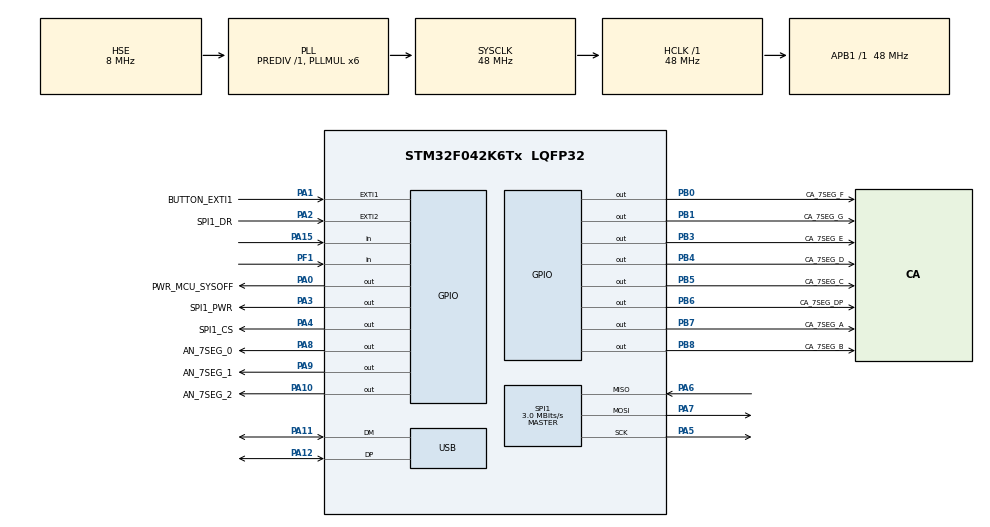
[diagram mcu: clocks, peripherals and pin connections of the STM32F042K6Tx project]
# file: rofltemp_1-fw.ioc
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Mcu.Family=STM32F0
Mcu.Name=STM32F042K6Tx
Mcu.Package=LQFP32
NVIC.EXTI0_1_IRQn=true\:0\:0\:false\:false\:true\:true
NVIC.EXTI2_3_IRQn=true\:0\:0\:false\:false\:true\:true
NVIC.SPI1_IRQn=true\:0\:0\:false\:false\:true\:true
NVIC.TIM2_IRQn=true\:0\:0\:false\:false\:true\:true
NVIC.USB_IRQn=true\:0\:0\:false\:false\:true\:true
PA0.GPIO_Label=PWR_MCU_SYSOFF
PA0.GPIO_ModeDefaultOutputPP=GPIO_MODE_OUTPUT_PP
PA0.PinState=GPIO_PIN_SET
PA0.Signal=GPIO_Output
PA1.GPIO_Label=BUTTON_EXTI1
PA1.GPIO_ModeDefaultEXTI=GPIO_MODE_IT_FALLING
PA1.Signal=GPXTI1
PA10.GPIO_Label=AN_7SEG_2
PA10.GPIO_Speed=GPIO_SPEED_FREQ_MEDIUM
PA10.PinState=GPIO_PIN_SET
PA10.Signal=GPIO_Output
PA11.Mode=Device
PA11.Signal=USB_DM
PA12.Mode=Device
PA12.Signal=USB_DP
PA13.Mode=Serial_Wire
PA13.Signal=SYS_SWDIO
PA14.Mode=Serial_Wire
PA14.Signal=SYS_SWCLK
PA15.Signal=GPIO_Input
PA2.GPIO_Label=SPI1_DR
PA2.GPIO_ModeDefaultEXTI=GPIO_MODE_IT_FALLING
PA2.GPIO_PuPd=GPIO_PULLUP
PA2.Signal=GPXTI2
PA3.GPIO_Label=SPI1_PWR
PA3.GPIO_PuPd=GPIO_NOPULL
PA3.Signal=GPIO_Output
PA4.GPIO_Label=SPI1_CS
PA4.Signal=GPIO_Output
PA5.Mode=Full_Duplex_Master
PA5.Signal=SPI1_SCK
PA6.Mode=Full_Duplex_Master
PA6.Signal=SPI1_MISO
PA7.Mode=Full_Duplex_Master
PA7.Signal=SPI1_MOSI
PA8.GPIO_Label=AN_7SEG_0
PA8.GPIO_Speed=GPIO_SPEED_FREQ_MEDIUM
PA8.PinState=GPIO_PIN_SET
PA8.Signal=GPIO_Output
PA9.GPIO_FMA9=__NULL
PA9.GPIO_Label=AN_7SEG_1
PA9.GPIO_Speed=GPIO_SPEED_FREQ_MEDIUM
PA9.PinState=GPIO_PIN_SET
PA9.Signal=GPIO_Output
PB0.GPIO_Label=CA_7SEG_F
PB0.GPIO_Speed=GPIO_SPEED_FREQ_MEDIUM
PB0.Signal=GPIO_Output
PB1.GPIO_Label=CA_7SEG_G
PB1.GPIO_Speed=GPIO_SPEED_FREQ_MEDIUM
PB1.Signal=GPIO_Output
PB3.GPIO_Label=CA_7SEG_E
PB3.GPIO_Speed=GPIO_SPEED_FREQ_MEDIUM
PB3.Signal=GPIO_Output
PB4.GPIO_Label=CA_7SEG_D
PB4.GPIO_Speed=GPIO_SPEED_FREQ_MEDIUM
PB4.Signal=GPIO_Output
PB5.GPIO_Label=CA_7SEG_C
PB5.GPIO_Speed=GPIO_SPEED_FREQ_MEDIUM
PB5.Signal=GPIO_Output
PB6.GPIO_Label=CA_7SEG_DP
PB6.GPIO_Speed=GPIO_SPEED_FREQ_MEDIUM
PB6.Signal=GPIO_Output
PB7.GPIO_Label=CA_7SEG_A
PB7.GPIO_Speed=GPIO_SPEED_FREQ_MEDIUM
PB7.Signal=GPIO_Output
PB8.GPIO_Label=CA_7SEG_B
PB8.GPIO_Speed=GPIO_SPEED_FREQ_MEDIUM
PB8.Signal=GPIO_Output
PF0-OSC_IN.Mode=HSE-External-Clock-Source
PF0-OSC_IN.Signal=RCC_OSC_IN
PF1-OSC_OUT.Signal=GPIO_Input
ProjectManager.HeapSize=0x200
ProjectManager.StackSize=0x400
ProjectManager.TargetToolchain=SW4STM32
RCC.AHBFreq_Value=48000000
RCC.APB1Freq_Value=48000000
RCC.APB1TimFreq_Value=48000000
RCC.HCLKFreq_Value=48000000
RCC.PLLMUL=RCC_PLL_MUL6
RCC.SYSCLKFreq_VALUE=48000000
RCC.SYSCLKSource=RCC_SYSCLKSOURCE_PLLCLK
RCC.USBClockSelection=RCC_USBCLKSOURCE_PLL
RCC.USBFreq_Value=48000000
RCC.VDD_VALUE=3.3
SPI1.BaudRatePrescaler=SPI_BAUDRATEPRESCALER_16
SPI1.CLKPhase=SPI_PHASE_2EDGE
SPI1.CLKPolarity=SPI_POLARITY_HIGH
SPI1.CalculateBaudRate=3.0 MBits/s
SPI1.DataSize=SPI_DATASIZE_8BIT
SPI1.Direction=SPI_DIRECTION_2LINES
SPI1.Mode=SPI_MODE_MASTER
SPI1.VirtualType=VM_MASTER
TIM2.Channel-PWM\ Generation1\ No\ Output=TIM_CHANNEL_1
TIM2.Period=1000
TIM2.Prescaler=120
TIM2.Pulse-PWM\ Generation1\ No\ Output=500
TIM2.TIM_MasterOutputTrigger=TIM_TRGO_RESET
TIM2.TIM_MasterSlaveMode=TIM_MASTERSLAVEMODE_DISABLE
USB.lpm_enable=ENABLE
USB_DEVICE.CLASS_NAME_FS=CDC
USB_DEVICE.VirtualMode=Cdc
USB_DEVICE.VirtualModeFS=Cdc_FS
VP_TIM2_VS_ClockSourceINT.Mode=Internal
VP_TIM2_VS_no_output1.Mode=PWM Generation1 No Output
VP_USB_DEVICE_VS_USB_DEVICE_CDC_FS.Mode=CDC_FS
board=rofltemp_1-fw

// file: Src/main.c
/**
  ******************************************************************************
  * File Name          : main.c
  * Description        : Main program body
  ******************************************************************************
  * This notice applies to any and all portions of this file
  * that are not between comment pairs USER CODE BEGIN and
  * USER CODE END. Other portions of this file, whether
  * inserted by the user or by software development tools
  * are owned by their respective copyright owners.
  *
  * Copyright (c) 2017 STMicroelectronics International N.V.
  * All rights reserved.
  *
  * Redistribution and use in source and binary forms, with or without
  * modification, are permitted, provided that the following conditions are met:
  *
  * 1. Redistribution of source code must retain the above copyright notice,
  *    this list of conditions and the following disclaimer.
  * 2. Redistributions in binary form must reproduce the above copyright notice,
  *    this list of conditions and the following disclaimer in the documentation
  *    and/or other materials provided with the distribution.
  * 3. Neither the name of STMicroelectronics nor the names of other
  *    contributors to this software may be used to endorse or promote products
  *    derived from this software without specific written permission.
  * 4. This software, including modifications and/or derivative works of this
  *    software, must execute solely and exclusively on microcontroller or
  *    microprocessor devices manufactured by or for STMicroelectronics.
  * 5. Redistribution and use of this software other than as permitted under
  *    this license is void and will automatically terminate your rights under
  *    this license.
  *
  * THIS SOFTWARE IS PROVIDED BY STMICROELECTRONICS AND CONTRIBUTORS "AS IS"
  * AND ANY EXPRESS, IMPLIED OR STATUTORY WARRANTIES, INCLUDING, BUT NOT
  * LIMITED TO, THE IMPLIED WARRANTIES OF MERCHANTABILITY, FITNESS FOR A
  * PARTICULAR PURPOSE AND NON-INFRINGEMENT OF THIRD PARTY INTELLECTUAL PROPERTY
  * RIGHTS ARE DISCLAIMED TO THE FULLEST EXTENT PERMITTED BY LAW. IN NO EVENT
  * SHALL STMICROELECTRONICS OR CONTRIBUTORS BE LIABLE FOR ANY DIRECT, INDIRECT,
  * INCIDENTAL, SPECIAL, EXEMPLARY, OR CONSEQUENTIAL DAMAGES (INCLUDING, BUT NOT
  * LIMITED TO, PROCUREMENT OF SUBSTITUTE GOODS OR SERVICES; LOSS OF USE, DATA,
  * OR PROFITS; OR BUSINESS INTERRUPTION) HOWEVER CAUSED AND ON ANY THEORY OF
  * LIABILITY, WHETHER IN CONTRACT, STRICT LIABILITY, OR TORT (INCLUDING
  * NEGLIGENCE OR OTHERWISE) ARISING IN ANY WAY OUT OF THE USE OF THIS SOFTWARE,
  * EVEN IF ADVISED OF THE POSSIBILITY OF SUCH DAMAGE.
  *
  ******************************************************************************
  */
#include "main.h"
#include "stm32f0xx_hal.h"
#include "spi.h"
#include "tim.h"
#include "usb_device.h"
#include "gpio.h"

/* USER CODE BEGIN Includes */
#include "MAX31865.h"
#include "sevseg.h"
/* USER CODE END Includes */

/* USER CODE BEGIN PV */

/* Private variables ---------------------------------------------------------*/

/* USER CODE END PV */

void SystemClock_Config(void);

/* USER CODE BEGIN PFP */
/* Private function prototypes -----------------------------------------------*/

/* USER CODE END PFP */

/* USER CODE BEGIN 0 */
uint32_t start_time = 0;
uint32_t auto_off_time = 5000;
/* USER CODE END 0 */

int main(void)
{

  /* MCU Configuration----------------------------------------------------------*/

  /* Reset of all peripherals, Initializes the Flash interface and the Systick. */
  HAL_Init();

  /* Configure the system clock */
  SystemClock_Config();

  /* Initialize all configured peripherals */
  MX_GPIO_Init();
  MX_SPI1_Init();
  MX_USB_DEVICE_Init();
  MX_TIM2_Init();

  /* USER CODE BEGIN 2 */
  initSevSeg();

  if ( initMAX31865() != 0 )
  {
    HAL_Delay( 1000 );
  }

  start_time = HAL_GetTick();
  /* USER CODE END 2 */

  /* Infinite loop */
  /* USER CODE BEGIN WHILE */
  while ( 1 )
  {
    handleMAX31865Devices();
    checkMAX31865WDG();
    HandleQueuedCommand();
    if ( HAL_GetTick() - start_time >= auto_off_time )
    {
    	HAL_GPIO_WritePin(GPIOA, GPIO_PIN_0, GPIO_PIN_RESET);
    }
  /* USER CODE END WHILE */

  }

}

/** System Clock Configuration
*/
void SystemClock_Config(void)
{

  RCC_OscInitTypeDef RCC_OscInitStruct;
  RCC_ClkInitTypeDef RCC_ClkInitStruct;
  RCC_PeriphCLKInitTypeDef PeriphClkInit;

    /**Initializes the CPU, AHB and APB busses clocks
    */
  RCC_OscInitStruct.OscillatorType = RCC_OSCILLATORTYPE_HSE;
  RCC_OscInitStruct.HSEState = RCC_HSE_BYPASS;
  RCC_OscInitStruct.HSIState = RCC_HSI_ON;
  RCC_OscInitStruct.PLL.PLLState = RCC_PLL_ON;
  RCC_OscInitStruct.PLL.PLLSource = RCC_PLLSOURCE_HSE;
  RCC_OscInitStruct.PLL.PLLMUL = RCC_PLL_MUL6;
  RCC_OscInitStruct.PLL.PREDIV = RCC_PREDIV_DIV1;
  if (HAL_RCC_OscConfig(&RCC_OscInitStruct) != HAL_OK)
  {
    _Error_Handler(__FILE__, __LINE__);
  }

    /**Initializes the CPU, AHB and APB busses clocks
    */
  RCC_ClkInitStruct.ClockType = RCC_CLOCKTYPE_HCLK|RCC_CLOCKTYPE_SYSCLK
                              |RCC_CLOCKTYPE_PCLK1;
  RCC_ClkInitStruct.SYSCLKSource = RCC_SYSCLKSOURCE_PLLCLK;
  RCC_ClkInitStruct.AHBCLKDivider = RCC_SYSCLK_DIV1;
  RCC_ClkInitStruct.APB1CLKDivider = RCC_HCLK_DIV1;

  if (HAL_RCC_ClockConfig(&RCC_ClkInitStruct, FLASH_LATENCY_1) != HAL_OK)
  {
    _Error_Handler(__FILE__, __LINE__);
  }

  PeriphClkInit.PeriphClockSelection = RCC_PERIPHCLK_USB;
  PeriphClkInit.UsbClockSelection = RCC_USBCLKSOURCE_PLL;

  if (HAL_RCCEx_PeriphCLKConfig(&PeriphClkInit) != HAL_OK)
  {
    _Error_Handler(__FILE__, __LINE__);
  }

    /**Configure the Systick interrupt time
    */
  HAL_SYSTICK_Config(HAL_RCC_GetHCLKFreq()/1000);

    /**Configure the Systick
    */
  HAL_SYSTICK_CLKSourceConfig(SYSTICK_CLKSOURCE_HCLK);

  /* SysTick_IRQn interrupt configuration */
  HAL_NVIC_SetPriority(SysTick_IRQn, 0, 0);
}

void _Error_Handler(char * file, int line)
{
  while ( 1 )
  {
  }
}

/************************ (C) COPYRIGHT STMicroelectronics *****END OF FILE****/
